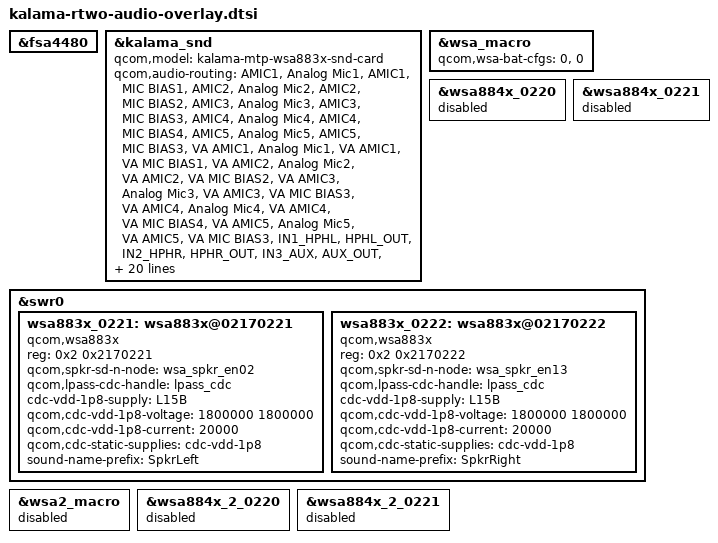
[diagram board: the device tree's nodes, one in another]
&fsa4480 {
	status = "ok";
};

&kalama_snd {
	qcom,model = "kalama-mtp-wsa883x-snd-card";
	qcom,audio-routing =
		"AMIC1", "Analog Mic1",
		"AMIC1", "MIC BIAS1",
		"AMIC2", "Analog Mic2",
		"AMIC2", "MIC BIAS2",
		"AMIC3", "Analog Mic3",
		"AMIC3", "MIC BIAS3",
		"AMIC4", "Analog Mic4",
		"AMIC4", "MIC BIAS4",
		"AMIC5", "Analog Mic5",
		"AMIC5", "MIC BIAS3",
		"VA AMIC1", "Analog Mic1",
		"VA AMIC1", "VA MIC BIAS1",
		"VA AMIC2", "Analog Mic2",
		"VA AMIC2", "VA MIC BIAS2",
		"VA AMIC3", "Analog Mic3",
		"VA AMIC3", "VA MIC BIAS3",
		"VA AMIC4", "Analog Mic4",
		"VA AMIC4", "VA MIC BIAS4",
		"VA AMIC5", "Analog Mic5",
		"VA AMIC5", "VA MIC BIAS3",
		"IN1_HPHL", "HPHL_OUT",
		"IN2_HPHR", "HPHR_OUT",
		"IN3_AUX", "AUX_OUT",
		"HAP_IN", "PCM_OUT",
		"WSA SRC0_INP", "SRC0",
		"WSA_TX DEC0_INP", "TX DEC0 MUX",
		"WSA_TX DEC1_INP", "TX DEC1 MUX",
		"RX_TX DEC0_INP", "TX DEC0 MUX",
		"RX_TX DEC1_INP", "TX DEC1 MUX",
		"RX_TX DEC2_INP", "TX DEC2 MUX",
		"RX_TX DEC3_INP", "TX DEC3 MUX",
		"SpkrLeft IN", "WSA_SPK1 OUT",
		"SpkrRight IN", "WSA_SPK2 OUT",
		"TX SWR_INPUT", "WCD_TX_OUTPUT",
		"VA SWR_INPUT", "VA_SWR_CLK",
		"VA SWR_INPUT", "WCD_TX_OUTPUT",
		"VA_AIF1 CAP", "VA_SWR_CLK",
		"VA_AIF2 CAP", "VA_SWR_CLK",
		"VA_AIF3 CAP", "VA_SWR_CLK";
	asoc-codec  = <&stub_codec>, <&lpass_cdc>,
			<&wcd938x_codec>, <&swr_haptics>,
			<&wsa883x_0221>, <&wsa883x_0222>;
	asoc-codec-names = "msm-stub-codec.1", "lpass-cdc",
			"wcd938x_codec", "swr-haptics",
			"wsa-codec1", "wsa-codec2";

	qcom,msm-mbhc-usbc-audio-supported = <1>;
	qcom,msm-mbhc-hphl-swh = <1>;
	qcom,msm-mbhc-gnd-swh = <1>;
};

&wsa_macro {
	qcom,wsa-bat-cfgs= <0>, <0>;
};

&wsa884x_0220 {
    status = "disabled";
};

&wsa884x_0221 {
    status = "disabled";
};

&swr0 {
	wsa883x_0221: wsa883x@02170221 {
		compatible = "qcom,wsa883x";
		reg = <0x2 0x2170221>;
		qcom,spkr-sd-n-node = <&wsa_spkr_en02>;
		qcom,lpass-cdc-handle = <&lpass_cdc>;
		cdc-vdd-1p8-supply = <&L15B>;
		qcom,cdc-vdd-1p8-voltage = <1800000 1800000>;
		qcom,cdc-vdd-1p8-current = <20000>;
		qcom,cdc-static-supplies = "cdc-vdd-1p8";
		sound-name-prefix = "SpkrLeft";
	};

	wsa883x_0222: wsa883x@02170222 {
		compatible = "qcom,wsa883x";
		reg = <0x2 0x2170222>;
		qcom,spkr-sd-n-node = <&wsa_spkr_en13>;
		qcom,lpass-cdc-handle = <&lpass_cdc>;
		cdc-vdd-1p8-supply = <&L15B>;
		qcom,cdc-vdd-1p8-voltage = <1800000 1800000>;
		qcom,cdc-vdd-1p8-current = <20000>;
		qcom,cdc-static-supplies = "cdc-vdd-1p8";
		sound-name-prefix = "SpkrRight";
	};
};

&wsa2_macro {
	status = "disabled";
};

&wsa884x_2_0220 {
    status = "disabled";
};

&wsa884x_2_0221 {
    status = "disabled";
};
